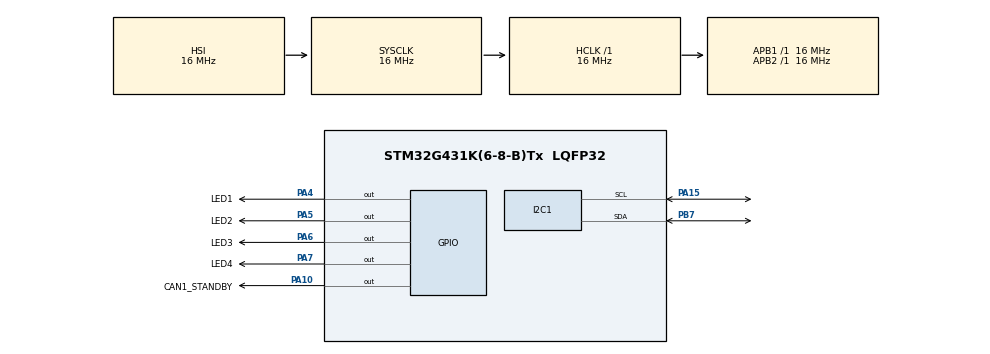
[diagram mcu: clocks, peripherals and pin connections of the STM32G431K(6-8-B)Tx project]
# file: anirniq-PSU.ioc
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Mcu.Family=STM32G4
I2C1.Speed=100
RCC.CortexFreq_Value=16000000
RCC.EXTERNAL_CLOCK_VALUE=12288000
PA6.GPIO_Label=LED3
ProjectManager.StackSize=0x400
PA13.Signal=SYS_JTMS-SWDIO
PA12.Signal=FDCAN1_TX
ProjectManager.TargetToolchain=STM32CubeIDE
RCC.HCLKFreq_Value=16000000
RCC.APB2TimFreq_Value=16000000
RCC.USBFreq_Value=64000000
RCC.LSE_VALUE=32768
RCC.AHBFreq_Value=16000000
PF0-OSC_IN.Mode=HSE-External-Oscillator
PA5.Signal=GPIO_Output
RCC.HSE_VALUE=8000000
board=custom
RCC.VCOOutputFreq_Value=128000000
PA15.Mode=I2C
RCC.APB2Freq_Value=16000000
PA14.Mode=Serial_Wire
PA10.GPIO_Label=CAN1_STANDBY
VP_SYS_VS_DBSignals.Mode=DisableDeadBatterySignals
PB7.Signal=I2C1_SDA
PA13.Mode=Serial_Wire
Mcu.Name=STM32G431K(6-8-B)Tx
PA4.Signal=GPIO_Output
RCC.SYSCLKFreq_VALUE=16000000
Mcu.Package=LQFP32
PA6.Signal=GPIO_Output
PA7.GPIO_Label=LED4
PA5.GPIO_Label=LED2
PB7.Mode=I2C
PA11.Signal=FDCAN1_RX
PA10.Signal=GPIO_Output
PA14.Signal=SYS_JTCK-SWCLK
PA15.Signal=I2C1_SCL
ProjectManager.HeapSize=0x200
RCC.HSI_VALUE=16000000
NVIC.PriorityGroup=NVIC_PRIORITYGROUP_4
RCC.APB1TimFreq_Value=16000000
PF0-OSC_IN.Signal=RCC_OSC_IN
PF1-OSC_OUT.Mode=HSE-External-Oscillator
RCC.APB1Freq_Value=16000000
PA4.GPIO_Label=LED1
PF1-OSC_OUT.Signal=RCC_OSC_OUT
RCC.HSI48_VALUE=48000000
PA7.Signal=GPIO_Output

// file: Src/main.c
/* USER CODE BEGIN Header */
/**
  ******************************************************************************
  * @file           : main.c
  * @brief          : Main program body
  ******************************************************************************
  * @attention
  *
  * <h2><center>&copy; Copyright (c) 2021 STMicroelectronics.
  * All rights reserved.</center></h2>
  *
  * This software component is licensed by ST under BSD 3-Clause license,
  * the "License"; You may not use this file except in compliance with the
  * License. You may obtain a copy of the License at:
  *                        opensource.org/licenses/BSD-3-Clause
  *
  ******************************************************************************
  */
/* USER CODE END Header */
#include "main.h"

I2C_HandleTypeDef hi2c1;

void SystemClock_Config(void);
static void MX_GPIO_Init(void);
static void MX_I2C1_Init(void);

int main(void)
{

  /* MCU Configuration--------------------------------------------------------*/

  /* Reset of all peripherals, Initializes the Flash interface and the Systick. */
  HAL_Init();

  /* Configure the system clock */
  SystemClock_Config();

  /* Initialize all configured peripherals */
  MX_GPIO_Init();
  MX_I2C1_Init();

  /* Infinite loop */
  while (1)
  {

    /* USER CODE BEGIN 3 */
	  HAL_GPIO_TogglePin(LED4_GPIO_Port, LED4_Pin);
  }
  /* USER CODE END 3 */
}

void SystemClock_Config(void)
{
  RCC_OscInitTypeDef RCC_OscInitStruct = {0};
  RCC_ClkInitTypeDef RCC_ClkInitStruct = {0};
  RCC_PeriphCLKInitTypeDef PeriphClkInit = {0};

  /** Configure the main internal regulator output voltage
  */
  HAL_PWREx_ControlVoltageScaling(PWR_REGULATOR_VOLTAGE_SCALE1);
  /** Initializes the RCC Oscillators according to the specified parameters
  * in the RCC_OscInitTypeDef structure.
  */
  RCC_OscInitStruct.OscillatorType = RCC_OSCILLATORTYPE_HSI;
  RCC_OscInitStruct.HSIState = RCC_HSI_ON;
  RCC_OscInitStruct.HSICalibrationValue = RCC_HSICALIBRATION_DEFAULT;
  RCC_OscInitStruct.PLL.PLLState = RCC_PLL_NONE;
  if (HAL_RCC_OscConfig(&RCC_OscInitStruct) != HAL_OK)
  {
    Error_Handler();
  }
  /** Initializes the CPU, AHB and APB buses clocks
  */
  RCC_ClkInitStruct.ClockType = RCC_CLOCKTYPE_HCLK|RCC_CLOCKTYPE_SYSCLK
                              |RCC_CLOCKTYPE_PCLK1|RCC_CLOCKTYPE_PCLK2;
  RCC_ClkInitStruct.SYSCLKSource = RCC_SYSCLKSOURCE_HSI;
  RCC_ClkInitStruct.AHBCLKDivider = RCC_SYSCLK_DIV1;
  RCC_ClkInitStruct.APB1CLKDivider = RCC_HCLK_DIV1;
  RCC_ClkInitStruct.APB2CLKDivider = RCC_HCLK_DIV1;

  if (HAL_RCC_ClockConfig(&RCC_ClkInitStruct, FLASH_LATENCY_0) != HAL_OK)
  {
    Error_Handler();
  }
  /** Initializes the peripherals clocks
  */
  PeriphClkInit.PeriphClockSelection = RCC_PERIPHCLK_I2C1;
  PeriphClkInit.I2c1ClockSelection = RCC_I2C1CLKSOURCE_PCLK1;
  if (HAL_RCCEx_PeriphCLKConfig(&PeriphClkInit) != HAL_OK)
  {
    Error_Handler();
  }
}

static void MX_I2C1_Init(void)
{

  hi2c1.Instance = I2C1;
  hi2c1.Init.Timing = 0x00303D5B;
  hi2c1.Init.OwnAddress1 = 0;
  hi2c1.Init.AddressingMode = I2C_ADDRESSINGMODE_7BIT;
  hi2c1.Init.DualAddressMode = I2C_DUALADDRESS_DISABLE;
  hi2c1.Init.OwnAddress2 = 0;
  hi2c1.Init.OwnAddress2Masks = I2C_OA2_NOMASK;
  hi2c1.Init.GeneralCallMode = I2C_GENERALCALL_DISABLE;
  hi2c1.Init.NoStretchMode = I2C_NOSTRETCH_DISABLE;
  if (HAL_I2C_Init(&hi2c1) != HAL_OK)
  {
    Error_Handler();
  }
  /** Configure Analogue filter
  */
  if (HAL_I2CEx_ConfigAnalogFilter(&hi2c1, I2C_ANALOGFILTER_ENABLE) != HAL_OK)
  {
    Error_Handler();
  }
  /** Configure Digital filter
  */
  if (HAL_I2CEx_ConfigDigitalFilter(&hi2c1, 0) != HAL_OK)
  {
    Error_Handler();
  }

}

static void MX_GPIO_Init(void)
{
  GPIO_InitTypeDef GPIO_InitStruct = {0};

  /* GPIO Ports Clock Enable */
  __HAL_RCC_GPIOF_CLK_ENABLE();
  __HAL_RCC_GPIOA_CLK_ENABLE();
  __HAL_RCC_GPIOB_CLK_ENABLE();

  /*Configure GPIO pin Output Level */
  HAL_GPIO_WritePin(GPIOA, LED1_Pin|LED2_Pin|LED3_Pin|LED4_Pin
                          |CAN1_STANDBY_Pin, GPIO_PIN_RESET);

  /*Configure GPIO pins : LED1_Pin LED2_Pin LED3_Pin LED4_Pin
                           CAN1_STANDBY_Pin */
  GPIO_InitStruct.Pin = LED1_Pin|LED2_Pin|LED3_Pin|LED4_Pin
                          |CAN1_STANDBY_Pin;
  GPIO_InitStruct.Mode = GPIO_MODE_OUTPUT_PP;
  GPIO_InitStruct.Pull = GPIO_NOPULL;
  GPIO_InitStruct.Speed = GPIO_SPEED_FREQ_LOW;
  HAL_GPIO_Init(GPIOA, &GPIO_InitStruct);

  /*Configure GPIO pins : PA11 PA12 */
  GPIO_InitStruct.Pin = GPIO_PIN_11|GPIO_PIN_12;
  GPIO_InitStruct.Mode = GPIO_MODE_AF_PP;
  GPIO_InitStruct.Pull = GPIO_NOPULL;
  GPIO_InitStruct.Speed = GPIO_SPEED_FREQ_LOW;
  GPIO_InitStruct.Alternate = GPIO_AF9_FDCAN1;
  HAL_GPIO_Init(GPIOA, &GPIO_InitStruct);

}

void Error_Handler(void)
{
}

/************************ (C) COPYRIGHT STMicroelectronics *****END OF FILE****/
